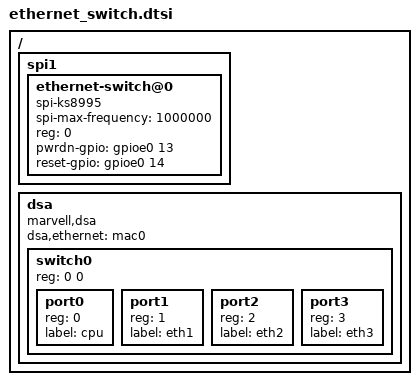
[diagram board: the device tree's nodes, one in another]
/ {
	spi1 {
		ethernet-switch@0 {
			compatible = "spi-ks8995";
			spi-max-frequency = <1000000>;
			reg = <0>;
			pwrdn-gpio = <&gpioe0 13 0>;
			reset-gpio = <&gpioe0 14 0>;
		};
	};

	dsa {
		compatible = "marvell,dsa";
		#address-cells = <2>;
		#size-cells = <0>;

		dsa,ethernet = <&mac0>;

		switch0 {
			#address-cells = <1>;
			#size-cells = <0>;
			reg = <0 0>;

			port0 {
				reg = <0>;
				label = "cpu";
			};

			port1 {
				reg = <1>;
				label = "eth1";
			};

			port2 {
				reg = <2>;
				label = "eth2";
			};

			port3 {
				reg = <3>;
				label = "eth3";
			};
		};
	};
};
